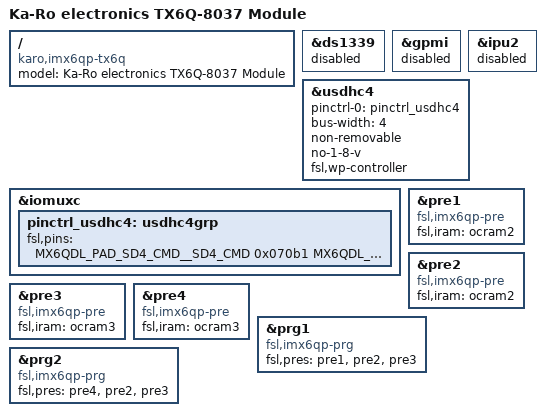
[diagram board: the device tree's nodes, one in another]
/*
 * Copyright 2017 Lothar Waßmann <LW@KARO-electronics.de>
 *
 * This file is dual-licensed: you can use it either under the terms
 * of the GPL or the X11 license, at your option. Note that this dual
 * licensing only applies to this file, and not this project as a
 * whole.
 *
 *  a) This file is free software; you can redistribute it and/or
 *     modify it under the terms of the GNU General Public License
 *     version 2 as published by the Free Software Foundation.
 *
 *     This file is distributed in the hope that it will be useful,
 *     but WITHOUT ANY WARRANTY; without even the implied warranty of
 *     MERCHANTABILITY or FITNESS FOR A PARTICULAR PURPOSE.  See the
 *     GNU General Public License for more details.
 *
 * Or, alternatively,
 *
 *  b) Permission is hereby granted, free of charge, to any person
 *     obtaining a copy of this software and associated documentation
 *     files (the "Software"), to deal in the Software without
 *     restriction, including without limitation the rights to use,
 *     copy, modify, merge, publish, distribute, sublicense, and/or
 *     sell copies of the Software, and to permit persons to whom the
 *     Software is furnished to do so, subject to the following
 *     conditions:
 *
 *     The above copyright notice and this permission notice shall be
 *     included in all copies or substantial portions of the Software.
 *
 *     THE SOFTWARE IS PROVIDED "AS IS", WITHOUT WARRANTY OF ANY KIND,
 *     EXPRESS OR IMPLIED, INCLUDING BUT NOT LIMITED TO THE WARRANTIES
 *     OF MERCHANTABILITY, FITNESS FOR A PARTICULAR PURPOSE AND
 *     NONINFRINGEMENT. IN NO EVENT SHALL THE AUTHORS OR COPYRIGHT
 *     HOLDERS BE LIABLE FOR ANY CLAIM, DAMAGES OR OTHER LIABILITY,
 *     WHETHER IN AN ACTION OF CONTRACT, TORT OR OTHERWISE, ARISING
 *     FROM, OUT OF OR IN CONNECTION WITH THE SOFTWARE OR THE USE OR
 *     OTHER DEALINGS IN THE SOFTWARE.
 */

/dts-v1/;
#include "imx6qp.dtsi"
#include "imx6qdl-tx6.dtsi"
#include "imx6qdl-tx6-lcd.dtsi"

/ {
	model = "Ka-Ro electronics TX6Q-8037 Module";
	compatible = "karo,imx6qp-tx6q", "fsl,imx6qp";
};

&ds1339 {
	status = "disabled";
};

&gpmi {
	status = "disabled";
};

&ipu2 {
	status = "disabled";
};

&usdhc4 {
	pinctrl-names = "default";
	pinctrl-0 = <&pinctrl_usdhc4>;
	bus-width = <4>;
	non-removable;
	no-1-8-v;
	fsl,wp-controller;
	status = "okay";
};

&iomuxc {
	pinctrl_usdhc4: usdhc4grp {
		fsl,pins = <
			MX6QDL_PAD_SD4_CMD__SD4_CMD		0x070b1
			MX6QDL_PAD_SD4_CLK__SD4_CLK		0x070b1
			MX6QDL_PAD_SD4_DAT0__SD4_DATA0		0x070b1
			MX6QDL_PAD_SD4_DAT1__SD4_DATA1		0x070b1
			MX6QDL_PAD_SD4_DAT2__SD4_DATA2		0x070b1
			MX6QDL_PAD_SD4_DAT3__SD4_DATA3		0x070b1
			MX6QDL_PAD_NANDF_ALE__SD4_RESET		0x0b0b1
		>;
	};
};

/*
 * imx6qp.dtsi comes from the NXP lf-6.6 BSP and describes the PRE/PRG in the
 * form expected by the fbdev IPU stack (drivers/mxc/ipu3): compatible
 * "fsl,imx6q-pre"/"fsl,imx6q-prg", an "ocram" phandle and "apb" clock, all
 * disabled.  This BSP builds the mainline DRM stack instead
 * (CONFIG_DRM_IMX_IPUV3=y, CONFIG_MXC_IPU unset), whose drivers only match
 * "fsl,imx6qp-pre"/"fsl,imx6qp-prg" and read "fsl,iram"/"fsl,pres".
 *
 * Nothing therefore binds to the PRE/PRG, while imx6qp.dtsi still points both
 * IPUs at them through "fsl,prg".  ipu_prg_lookup_by_phandle() returns NULL and
 * ipu_probe() bails out with -EPROBE_DEFER for good, so imx-drm never binds and
 * the board comes up without any display at all.
 *
 * Restore the binding documented in
 * Documentation/devicetree/bindings/display/imx/fsl-imx-drm.txt, which is what
 * the 5.10 device tree of these modules used.
 */
&pre1 {
	compatible = "fsl,imx6qp-pre";
	/delete-property/ ocram;
	fsl,iram = <&ocram2>;
	status = "okay";
};

&pre2 {
	compatible = "fsl,imx6qp-pre";
	/delete-property/ ocram;
	fsl,iram = <&ocram2>;
	status = "okay";
};

&pre3 {
	compatible = "fsl,imx6qp-pre";
	/delete-property/ ocram;
	fsl,iram = <&ocram3>;
	status = "okay";
};

&pre4 {
	compatible = "fsl,imx6qp-pre";
	/delete-property/ ocram;
	fsl,iram = <&ocram3>;
	status = "okay";
};

&prg1 {
	compatible = "fsl,imx6qp-prg";
	clock-names = "ipg", "axi";
	fsl,pres = <&pre1>, <&pre2>, <&pre3>;
	status = "okay";
};

&prg2 {
	compatible = "fsl,imx6qp-prg";
	clock-names = "ipg", "axi";
	fsl,pres = <&pre4>, <&pre2>, <&pre3>;
	status = "okay";
};
